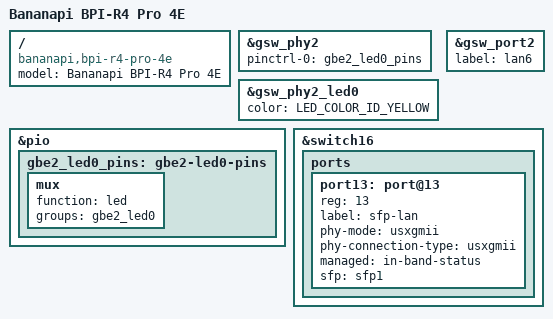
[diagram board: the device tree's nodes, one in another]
// SPDX-License-Identifier: (GPL-2.0 OR MIT)
/*
 * Copyright (C) 2025 MediaTek Inc.
 * Author: Frank Wunderlich <frank-w@public-files.de>
 */

/dts-v1/;

#include "mt7988a-bananapi-bpi-r4-pro.dtsi"

/ {
	model = "Bananapi BPI-R4 Pro 4E";
	compatible = "bananapi,bpi-r4-pro-4e",
		     "bananapi,bpi-r4-pro",
		     "mediatek,mt7988a";
};

&gsw_phy2 {
	pinctrl-0 = <&gbe2_led0_pins>;
	pinctrl-names = "gbe-led";
	status = "okay";
};

&gsw_phy2_led0 {
	color = <LED_COLOR_ID_YELLOW>;
	status = "okay";
};

&gsw_port2 {
	label = "lan6";
	status = "okay";
};

&pio {
	gbe2_led0_pins: gbe2-led0-pins {
		mux {
			function = "led";
			groups = "gbe2_led0";
		};
	};
};

&switch16 {
	ports {
		port13: port@13 {
			reg = <13>;
			label = "sfp-lan";
			phy-mode = "usxgmii";
			phy-connection-type = "usxgmii";
			managed = "in-band-status";
			sfp = <&sfp1>;

			status = "okay";
		};
	};
};
